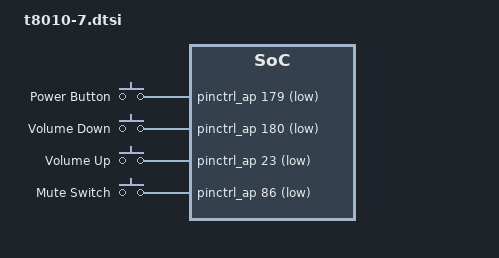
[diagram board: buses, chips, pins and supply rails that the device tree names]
// SPDX-License-Identifier: GPL-2.0+ OR MIT
/*
 * Apple iPhone 7 / 7 Plus common device tree
 *
 * Copyright (c) 2022, Konrad Dybcio <konradybcio@kernel.org>
 */

#include "t8010.dtsi"
#include "t8010-common.dtsi"
#include <dt-bindings/input/input.h>

/ {
	chassis-type = "handset";

	gpio-keys {
		compatible = "gpio-keys";

		button-power {
			label = "Power Button";
			gpios = <&pinctrl_ap 179 GPIO_ACTIVE_LOW>;
			linux,code = <KEY_POWER>;
			wakeup-source;
		};

		button-voldown {
			label = "Volume Down";
			gpios = <&pinctrl_ap 180 GPIO_ACTIVE_LOW>;
			linux,code = <KEY_VOLUMEDOWN>;
		};

		button-volup {
			label = "Volume Up";
			gpios = <&pinctrl_ap 23 GPIO_ACTIVE_LOW>;
			linux,code = <KEY_VOLUMEUP>;
		};

		switch-mute {
			label = "Mute Switch";
			gpios = <&pinctrl_ap 86 GPIO_ACTIVE_LOW>;
			linux,code = <KEY_MUTE>;
		};
	};
};
